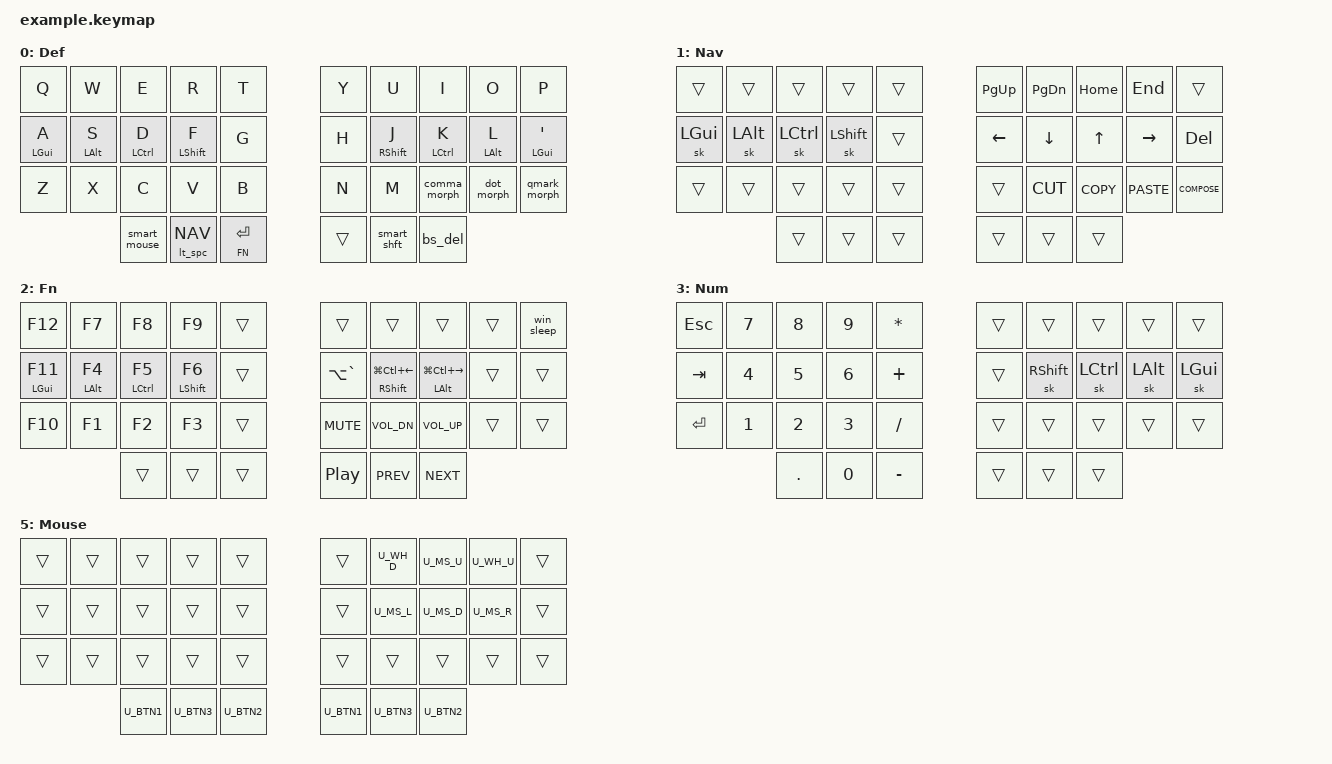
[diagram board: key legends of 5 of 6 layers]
#include <behaviors.dtsi>
#include <dt-bindings/zmk/keys.h>

/* layer and key shortcuts */
#include <dt-bindings/zmk/bt.h>

#define _BT_SEL_KEYS_ &bt BT_SEL 0 &bt BT_SEL 1 &bt BT_SEL 2 &bt BT_SEL 3 &bt BT_CLR

#define DEF 0  // layer shortcuts, must match order in which they are defined below
#define NAV 1
#define FN 2
#define NUM 3
#define SYS 4
#define MOUSE 5

#define KEYS_L LT0 LT1 LT2 LT3 LT4 LM0 LM1 LM2 LM3 LM4 LB0 LB1 LB2 LB3 LB4  // left hand
#define KEYS_R RT0 RT1 RT2 RT3 RT4 RM0 RM1 RM2 RM3 RM4 RB0 RB1 RB2 RB3 RB4  // right hand
#define KEYS_T LH2 LH1 LH0 RH0 RH1 RH2   // thumbs

#include "includes/macros.dtsi"
#include "includes/mods.dtsi"
#include "includes/dance.dtsi"
#include "includes/combos.dtsi"
#include "includes/morphs.dtsi" // requires layer aliases
#include "includes/mouse.dtsi"

#define XXX &none
#define ___ &trans

/* Global settings */


&sk {  // sticky-key config
    release-after-ms = <900>;  // release after 0.6s
    quick-release;             // no double capitalization when rolling keys
};

&mt {
  tapping-term-ms = <200>;
};

&lt {  // layer-tap config
  flavor = "balanced";
  tapping-term-ms = <200>;
  require-prior-idle-ms = <175>;
};

&sl {  // sticky-layer config
    ignore-modifiers;          // allow chording sticky mods & layers
};


#define PASTE LS(INS)
#define COMPOSE K_CMENU
// misc aliases
#define CANCEL      &kp K_CANCEL             // cancel caps-word, num-word and smart-mouse
#define DSK_PREV    &hmr RSHFT LG(LC(LEFT))  // previous desktop
#define DSK_NEXT    &hmr LALT LG(LC(RIGHT))  // next     desktop
#define DSK_MGR     &kp LA(GRAVE)            // desktop manager

&caps_word {  // mods deactivate caps-word, requires PR #1451
    /delete-property/ ignore-modifiers;
};

// tap: num-word | double-tap: sticky num-layer | hold: num-layer
#define SMART_NUM &smart_num NUM 0


&num_word {  // num-word, requires PR #1451
    layers = <NUM>;
    continue-list = <BSPC DEL DOT COMMA PLUS MINUS STAR FSLH EQUAL>;
};


/* keymap */
/ {
  conditional_layers {
        compatible = "zmk,conditional-layers";
        tri_layer {
            if-layers = <FN NUM>;
            then-layer = <SYS>;
        };
    };

  keymap {
    compatible = "zmk,keymap";

  def_layer {
    label ="Def";
    bindings = <
     // ╭─────────────┬─────────────┬─────────────┬─────────────┬─────────────╮   ╭─────────────┬─────────────┬─────────────┬─────────────┬─────────────╮
          &kp Q         &kp W         &kp E         &kp R         &kp T             &kp Y         &kp U         &kp I         &kp O         &kp P  
     // ├─────────────┼─────────────┼─────────────┼─────────────┼─────────────┤   ├─────────────┼─────────────┼─────────────┼─────────────┼─────────────┤
          &hml LGUI A   &hml LALT S   &hml LCTRL D  &hml LSHFT F  &kp G             &kp H         &hmr RSHFT J  &hmr LCTRL K  &hmr LALT L   &hmr LGUI SQT
     // ├─────────────┼─────────────┼─────────────┼─────────────┼─────────────┤   ├─────────────┼─────────────┼─────────────┼─────────────┼─────────────┤
          &kp Z         &kp X         &kp C         &kp V         &kp B             &kp N         &kp M         &comma_morph  &dot_morph   &qmark_morph
     // ╰─────────────┼─────────────┼─────────────┼─────────────┼─────────────┤   ├─────────────┼─────────────┼─────────────┼─────────────┼─────────────┤
                                      &smart_mouse  &lt_spc NAV   &lt FN RET        ___           &smart_shft   &bs_del
     //                             ╰─────────────┴─────────────┴─────────────╯   ╰─────────────┴─────────────┴─────────────╯
    >;
  };

  nav_layer {
    label = "Nav";
    bindings = <
     // ╭─────────────┬─────────────┬─────────────┬─────────────┬─────────────╮   ╭─────────────┬─────────────┬─────────────┬─────────────┬─────────────╮
          ___           ___           ___           ___           ___               &kp PG_UP     &kp PG_DN     &kp HOME      &kp END        ___         
     // ├─────────────┼─────────────┼─────────────┼─────────────┼─────────────┤   ├─────────────┼─────────────┼─────────────┼─────────────┼─────────────┤
          &sk LGUI      &sk LALT      &sk LCTRL     &sk LSHFT     ___               &kp LEFT      &kp DOWN      &kp UP        &kp RIGHT     &kp DEL      
     // ├─────────────┼─────────────┼─────────────┼─────────────┼─────────────┤   ├─────────────┼─────────────┼─────────────┼─────────────┼─────────────┤
          ___           ___           ___           ___           ___               ___           &kp CUT       &kp COPY      &kp PASTE     &kp COMPOSE  
     // ╰─────────────┼─────────────┼─────────────┼─────────────┼─────────────┤   ├─────────────┼─────────────┼─────────────┼─────────────┼─────────────┤
                                      ___           ___           ___               ___           ___           ___
     //                             ╰─────────────┴─────────────┴─────────────╯   ╰─────────────┴─────────────┴─────────────╯
    >;
  };

  fn_layer {
    label = "Fn";
    bindings = <
// ╭─────────────┬─────────────┬─────────────┬─────────────┬─────────────╮   ╭─────────────┬─────────────┬─────────────┬─────────────┬─────────────╮
          &kp F12       &kp F7        &kp F8        &kp F9        ___               ___           ___           ___           ___           &win_sleep   
     // ├─────────────┼─────────────┼─────────────┼─────────────┼─────────────┤   ├─────────────┼─────────────┼─────────────┼─────────────┼─────────────┤
          &hml LGUI F11 &hml LALT F4  &hml LCTRL F5 &hml LSHFT F6 ___               DSK_MGR       DSK_PREV      DSK_NEXT      ___           ___
     // ├─────────────┼─────────────┼─────────────┼─────────────┼─────────────┤   ├─────────────┼─────────────┼─────────────┼─────────────┼─────────────┤
          &kp F10       &kp F1        &kp F2        &kp F3        ___               &kp C_MUTE    &kp C_VOL_DN  &kp C_VOL_UP  ___           ___
     // ╰─────────────┼─────────────|─────────────┼─────────────┼─────────────┤   ├─────────────┼─────────────┼─────────────┴───────────────────────────╯
                                           ___      ___           ___               &kp C_PP      &kp C_PREV    &kp C_NEXT                               
     //                             |             ╰─────────────┴─────────────╯   ╰─────────────┴─────────────╯                                          
  >;
  };

  num_layer {
    label = "Num";
    bindings = <
     // ╭─────────────┬─────────────┬─────────────┬─────────────┬─────────────╮   ╭─────────────┬─────────────┬─────────────┬─────────────┬─────────────╮
          &kp ESC       &kp N7        &kp N8        &kp N9        &kp STAR          ___           ___           ___           ___           ___
     // ├─────────────┼─────────────┼─────────────┼─────────────┼─────────────┤   ├─────────────┼─────────────┼─────────────┼─────────────┼─────────────┤
          &kp TAB       &kp N4        &kp N5        &kp N6        &kp PLUS          ___           &sk RSHFT     &sk LCTRL     &sk LALT      &sk LGUI
     // ├─────────────┼─────────────┼─────────────┼─────────────┼─────────────┤   ├─────────────┼─────────────┼─────────────┼─────────────┼─────────────┤
          &kp RET       &kp N1        &kp N2        &kp N3        &kp FSLH          ___           ___           ___           ___           ___
     // ╰─────────────┼─────────────┼─────────────┼─────────────┼─────────────┤   ├─────────────┼─────────────┼─────────────┼─────────────┼─────────────┤
                                      &kp DOT       &kp N0        &kp MINUS         ___           ___           ___
     //                             ╰─────────────┴─────────────┴─────────────╯   ╰─────────────┴─────────────┴─────────────╯
    >;
  };

  sys_layer {
    label = "Sys";
    bindings = <
     // ╭─────────────┬─────────────┬─────────────┬─────────────┬─────────────╮   ╭─────────────┬─────────────┬─────────────┬─────────────┬─────────────╮
                                     _BT_SEL_KEYS_                                  ___           ___           ___           ___           ___          
     // ├─────────────┼─────────────┼─────────────┼─────────────┼─────────────┤   ├─────────────┼─────────────┼─────────────┼─────────────┼─────────────┤
          ___           ___           ___           ___           &bootloader       &bootloader   ___           ___           ___           ___          
     // ├─────────────┼─────────────┼─────────────┼─────────────┼─────────────┤   ├─────────────┼─────────────┼─────────────┼─────────────┼─────────────┤
          ___           ___           ___           ___           &sys_reset        &sys_reset    ___           ___           ___           ___          
     // ╰─────────────┼─────────────┼─────────────┼─────────────┼─────────────┤   ├─────────────┼─────────────┼─────────────┴───────────────────────────╯
                                      ___           ___           ___               ___           ___           ___                                      
     //                             ╰─────────────┴─────────────┴─────────────╯   ╰─────────────┴─────────────╯                                          
    >;
  };

  mouse_layer {
    label = "Mouse";
    bindings = <
     // ╭─────────────┬─────────────┬─────────────┬─────────────┬─────────────╮   ╭─────────────┬─────────────┬─────────────┬─────────────┬─────────────╮
          ___           ___           ___           ___           ___               ___           U_WH_D        U_MS_U         U_WH_U       ___          
     // ├─────────────┼─────────────┼─────────────┼─────────────┼─────────────┤   ├─────────────┼─────────────┼─────────────┼─────────────┼─────────────┤
          ___           ___           ___           ___           ___               ___           U_MS_L        U_MS_D         U_MS_R       ___          
     // ├─────────────┼─────────────┼─────────────┼─────────────┼─────────────┤   ├─────────────┼─────────────┼─────────────┼─────────────┼─────────────┤
          ___           ___           ___           ___           ___               ___           ___           ___            ___          ___          
     // ╰─────────────┼─────────────┴─────────────┼─────────────┼─────────────┤   ├─────────────┼─────────────┼─────────────┴───────────────────────────╯
                                      U_BTN1         U_BTN3       U_BTN2            U_BTN1        U_BTN3        U_BTN2                                         
     //                                           ╰─────────────┴─────────────╯   ╰─────────────┴─────────────╯                                          
  >;
  };
 };
};
  /* vim: set filetype=c : */
